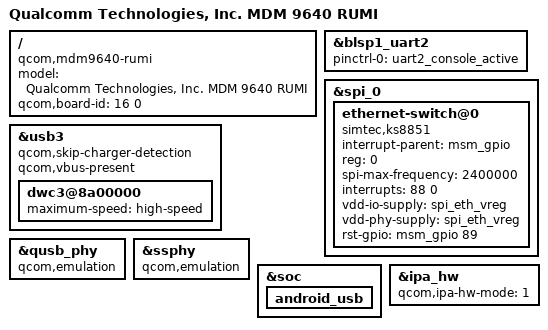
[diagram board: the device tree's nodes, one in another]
/* Copyright (c) 2014-2015, The Linux Foundation. All rights reserved.
 *
 * This program is free software; you can redistribute it and/or modify
 * it under the terms of the GNU General Public License version 2 and
 * only version 2 as published by the Free Software Foundation.
 *
 * This program is distributed in the hope that it will be useful,
 * but WITHOUT ANY WARRANTY; without even the implied warranty of
 * MERCHANTABILITY or FITNESS FOR A PARTICULAR PURPOSE.  See the
 * GNU General Public License for more details.
 */

/dts-v1/;

#include "mdm9640.dtsi"
#include "mdm9640-pinctrl.dtsi"

/ {
	model = "Qualcomm Technologies, Inc. MDM 9640 RUMI";
	compatible = "qcom,mdm9640-rumi", "qcom,mdm9640", "qcom,rumi";
	qcom,board-id = <16 0>;
};

&blsp1_uart2 {
	status = "ok";
	pinctrl-names = "default";
	pinctrl-0 = <&uart2_console_active>;
};

&spi_0 {
	status = "ok";
	ethernet-switch@0 {
		compatible = "simtec,ks8851";
		interrupt-parent = <&msm_gpio>;
		reg = <0>;
		spi-max-frequency = <2400000>;
		interrupts = <88 0>;
		vdd-io-supply = <&spi_eth_vreg>;
		vdd-phy-supply = <&spi_eth_vreg>;
		rst-gpio = <&msm_gpio 89 0>;
	};
};

&usb3 {
	status = "ok";
	qcom,skip-charger-detection;
	qcom,vbus-present;
	dwc3@8a00000 {
		maximum-speed = "high-speed";
	};
};

&qusb_phy {
	status = "ok";
	qcom,emulation;
};

&ssphy {
	status = "ok";
	qcom,emulation;
};

&soc {
	android_usb {
		status = "ok";
	};

};

&ipa_hw {
	qcom,ipa-hw-mode = <1>; /* IPA hw type = Virtual */
};
